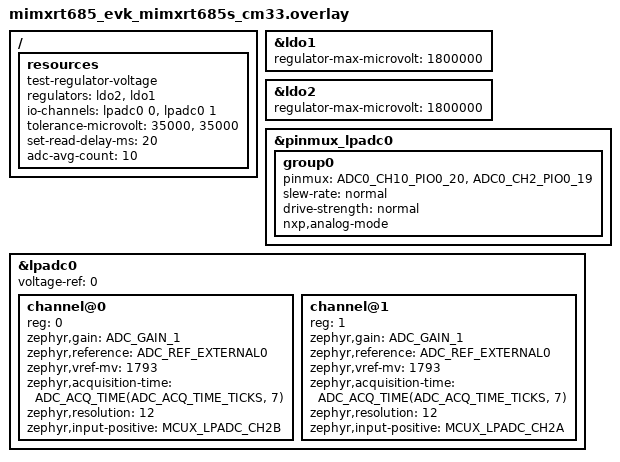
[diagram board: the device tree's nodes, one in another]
/*
 * Copyright 2022, 2025 NXP
 * SPDX-License-Identifier: Apache-2.0
 */

#include <zephyr/dt-bindings/adc/mcux-lpadc.h>

/* RT685 ADC only supports up to 1.8V,
 * so limit regulator voltage to this range.
 * Only test regulators we can safely change voltage to in RUN mode
 */
&ldo1 {
	regulator-max-microvolt = <1800000>;
};

&ldo2 {
	regulator-max-microvolt = <1800000>;
};

/* Override LPADC0 pinctrl settings */
&pinmux_lpadc0 {
	group0 {
		pinmux = <ADC0_CH10_PIO0_20>,
				<ADC0_CH2_PIO0_19>;
		slew-rate = "normal";
		drive-strength = "normal";
		nxp,analog-mode;
	};
};

/ {
	/* In this case, the LPADC reference source is set to set to VREFP (VREF_H),
	 * The user needs to measure the voltage of VREF_H pin to set the value of
	 * 'zephyr,vref-mv'.
	 *
	 * Note: make the following connections to run test on an RT685:
	 * J30.4 (ADC channel0) -> JS11.1 (LDO2 output)
	 * J30.3 (ADC channel1) -> JP26.1 (LDO1 output)
	 * Connect VREF_L to GND, and VREF_H to 1.8V (connect JP9 and JP10).
	 */
	resources: resources {
		compatible = "test-regulator-voltage";
		/* Note: LDO2 voltage range needs to be tested first
		 * to pass this test. It seems that when LDO2 is at the
		 * default voltage of 3.3V, LDO1 will not always deliver
		 * a voltage within given tolerance
		 */
		regulators = <&ldo2 &ldo1>;
		io-channels = <&lpadc0 0>, <&lpadc0 1>;
		tolerance-microvolt = <35000>, <35000>;
		set-read-delay-ms = <20>;
		adc-avg-count = <10>;
	};
};

&lpadc0 {
	#address-cells = <1>;
	#size-cells = <0>;

	/* In this case, the LPADC reference source is set to VREFP(VREF_H),
	 * The user needs to measure the voltage of VREFP pin to set the
	 * value of 'zephyr,vref-mv'.
	 */
	voltage-ref= <0>;

	channel@0 {
		reg = <0>;
		zephyr,gain = "ADC_GAIN_1";
		zephyr,reference = "ADC_REF_EXTERNAL0";
		zephyr,vref-mv = <1793>;
		zephyr,acquisition-time = <ADC_ACQ_TIME(ADC_ACQ_TIME_TICKS, 7)>;
		zephyr,resolution = <12>;
		zephyr,input-positive = <MCUX_LPADC_CH2B>;
	};

	channel@1 {
		reg = <1>;
		zephyr,gain = "ADC_GAIN_1";
		zephyr,reference = "ADC_REF_EXTERNAL0";
		zephyr,vref-mv = <1793>;
		zephyr,acquisition-time = <ADC_ACQ_TIME(ADC_ACQ_TIME_TICKS, 7)>;
		zephyr,resolution = <12>;
		zephyr,input-positive = <MCUX_LPADC_CH2A>;
	};
};
